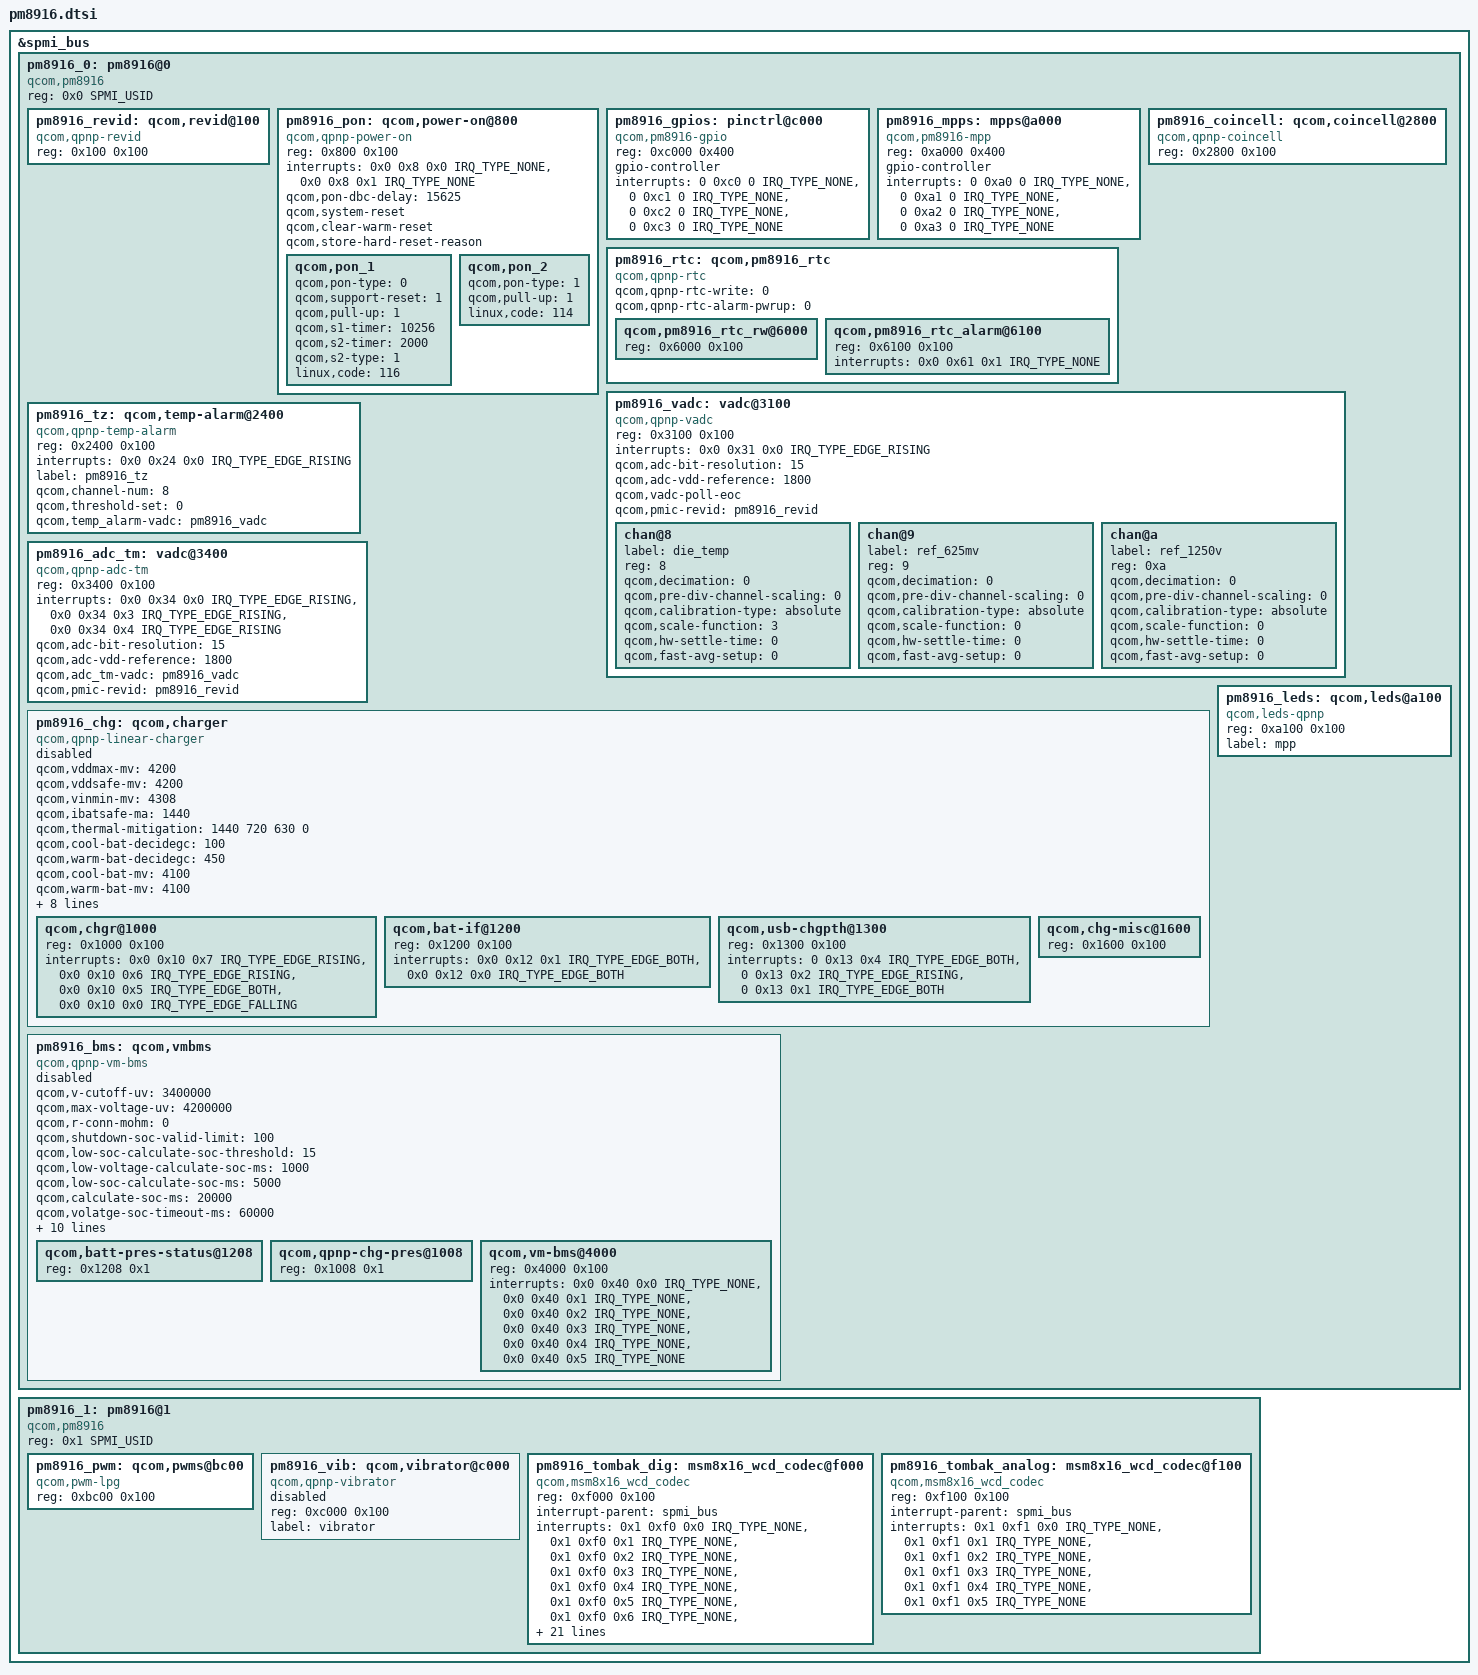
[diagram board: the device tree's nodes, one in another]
/* Copyright (c) 2013-2014, 2016-2018, The Linux Foundation. All rights reserved.
 *
 * This program is free software; you can redistribute it and/or modify
 * it under the terms of the GNU General Public License version 2 and
 * only version 2 as published by the Free Software Foundation.
 *
 * This program is distributed in the hope that it will be useful,
 * but WITHOUT ANY WARRANTY; without even the implied warranty of
 * MERCHANTABILITY or FITNESS FOR A PARTICULAR PURPOSE.  See the
 * GNU General Public License for more details.
 */

#include <dt-bindings/interrupt-controller/irq.h>
#include <dt-bindings/spmi/spmi.h>

&spmi_bus {

	pm8916_0: pm8916@0 {
		compatible = "qcom,pm8916", "qcom,spmi-pmic";
		reg = <0x0 SPMI_USID>;
		#address-cells = <1>;
		#size-cells = <1>;

		pm8916_revid: qcom,revid@100 {
			compatible = "qcom,qpnp-revid";
			reg = <0x100 0x100>;
		};

		pm8916_pon: qcom,power-on@800 {
			compatible = "qcom,qpnp-power-on";
			reg = <0x800 0x100>;
			interrupts = <0x0 0x8 0x0 IRQ_TYPE_NONE>,
				     <0x0 0x8 0x1 IRQ_TYPE_NONE>;
			interrupt-names = "kpdpwr", "resin";
			qcom,pon-dbc-delay = <15625>;
			qcom,system-reset;
			qcom,clear-warm-reset;
			qcom,store-hard-reset-reason;

			qcom,pon_1 {
				qcom,pon-type = <0>;
				qcom,support-reset = <1>;
				qcom,pull-up = <1>;
				qcom,s1-timer = <10256>;
				qcom,s2-timer = <2000>;
				qcom,s2-type = <1>;
				linux,code = <116>;
			};

			qcom,pon_2 {
				qcom,pon-type = <1>;
				qcom,pull-up = <1>;
				linux,code = <114>;
			};
		};

		pm8916_gpios: pinctrl@c000 {
			compatible = "qcom,pm8916-gpio";
			reg = <0xc000 0x400>;
			gpio-controller;
			#gpio-cells = <2>;
			interrupts = <0 0xc0 0 IRQ_TYPE_NONE>,
				     <0 0xc1 0 IRQ_TYPE_NONE>,
				     <0 0xc2 0 IRQ_TYPE_NONE>,
				     <0 0xc3 0 IRQ_TYPE_NONE>;
			interrupt-names = "pm8916_gpio1", "pm8916_gpio2",
					  "pm8916_gpio3", "pm8916_gpio4";
		};

		pm8916_mpps: mpps@a000 {
			compatible = "qcom,pm8916-mpp";
			reg = <0xa000 0x400>;
			gpio-controller;
			#gpio-cells = <2>;
			interrupts = <0 0xa0 0 IRQ_TYPE_NONE>,
				     <0 0xa1 0 IRQ_TYPE_NONE>,
				     <0 0xa2 0 IRQ_TYPE_NONE>,
				     <0 0xa3 0 IRQ_TYPE_NONE>;
			interrupt-names = "pm8916_mpp1", "pm8916_mpp2",
					  "pm8916_mpp3", "pm8916_mpp4";
		};

		pm8916_coincell: qcom,coincell@2800 {
			compatible = "qcom,qpnp-coincell";
			reg = <0x2800 0x100>;
		};

		pm8916_rtc: qcom,pm8916_rtc {
			compatible = "qcom,qpnp-rtc";
			#address-cells = <1>;
			#size-cells = <1>;
			qcom,qpnp-rtc-write = <0>;
			qcom,qpnp-rtc-alarm-pwrup = <0>;

			qcom,pm8916_rtc_rw@6000 {
				reg = <0x6000 0x100>;
			};
			qcom,pm8916_rtc_alarm@6100 {
				reg = <0x6100 0x100>;
				interrupts = <0x0 0x61 0x1 IRQ_TYPE_NONE>;
			};
		};

		pm8916_vadc: vadc@3100 {
			compatible = "qcom,qpnp-vadc";
			reg = <0x3100 0x100>;
			#address-cells = <1>;
			#size-cells = <0>;
			interrupts = <0x0 0x31 0x0 IRQ_TYPE_EDGE_RISING>;
			interrupt-names = "eoc-int-en-set";
			qcom,adc-bit-resolution = <15>;
			qcom,adc-vdd-reference = <1800>;
			qcom,vadc-poll-eoc;
			qcom,pmic-revid = <&pm8916_revid>;
			#thermal-sensor-cells = <1>;

			chan@8 {
				label = "die_temp";
				reg = <8>;
				qcom,decimation = <0>;
				qcom,pre-div-channel-scaling = <0>;
				qcom,calibration-type = "absolute";
				qcom,scale-function = <3>;
				qcom,hw-settle-time = <0>;
				qcom,fast-avg-setup = <0>;
			};

			chan@9 {
				label = "ref_625mv";
				reg = <9>;
				qcom,decimation = <0>;
				qcom,pre-div-channel-scaling = <0>;
				qcom,calibration-type = "absolute";
				qcom,scale-function = <0>;
				qcom,hw-settle-time = <0>;
				qcom,fast-avg-setup = <0>;
			};

			chan@a {
				label = "ref_1250v";
				reg = <0xa>;
				qcom,decimation = <0>;
				qcom,pre-div-channel-scaling = <0>;
				qcom,calibration-type = "absolute";
				qcom,scale-function = <0>;
				qcom,hw-settle-time = <0>;
				qcom,fast-avg-setup = <0>;
			};
		};

		pm8916_tz: qcom,temp-alarm@2400 {
			compatible = "qcom,qpnp-temp-alarm";
			reg = <0x2400 0x100>;
			interrupts = <0x0 0x24 0x0 IRQ_TYPE_EDGE_RISING>;
			label = "pm8916_tz";
			qcom,channel-num = <8>;
			qcom,threshold-set = <0>;
			qcom,temp_alarm-vadc = <&pm8916_vadc>;
			#thermal-sensor-cells = <0>;
		};

		pm8916_adc_tm: vadc@3400 {
			compatible = "qcom,qpnp-adc-tm";
			reg = <0x3400 0x100>;
			#address-cells = <1>;
			#size-cells = <0>;
			interrupts = <0x0 0x34 0x0 IRQ_TYPE_EDGE_RISING>,
				     <0x0 0x34 0x3 IRQ_TYPE_EDGE_RISING>,
				     <0x0 0x34 0x4 IRQ_TYPE_EDGE_RISING>;
			interrupt-names = "eoc-int-en-set",
					  "high-thr-en-set",
					  "low-thr-en-set";
			qcom,adc-bit-resolution = <15>;
			qcom,adc-vdd-reference = <1800>;
			qcom,adc_tm-vadc = <&pm8916_vadc>;
			qcom,pmic-revid = <&pm8916_revid>;
		};

		pm8916_chg: qcom,charger {
			compatible = "qcom,qpnp-linear-charger";
			#address-cells = <1>;
			#size-cells = <1>;

			qcom,vddmax-mv = <4200>;
			qcom,vddsafe-mv = <4200>;
			qcom,vinmin-mv = <4308>;
			qcom,ibatsafe-ma = <1440>;
			qcom,thermal-mitigation = <1440 720 630 0>;
			qcom,cool-bat-decidegc = <100>;
			qcom,warm-bat-decidegc = <450>;
			qcom,cool-bat-mv = <4100>;
			qcom,warm-bat-mv = <4100>;
			qcom,ibatmax-warm-ma = <360>;
			qcom,ibatmax-cool-ma = <360>;
			qcom,batt-hot-percentage = <25>;
			qcom,batt-cold-percentage = <80>;
			qcom,tchg-mins = <232>;
			qcom,resume-soc = <99>;
			qcom,chg-vadc = <&pm8916_vadc>;
			qcom,chg-adc_tm = <&pm8916_adc_tm>;

			status = "disabled";

			qcom,chgr@1000 {
				reg = <0x1000 0x100>;
				interrupts =
					<0x0 0x10 0x7 IRQ_TYPE_EDGE_RISING>,
					<0x0 0x10 0x6 IRQ_TYPE_EDGE_RISING>,
					<0x0 0x10 0x5 IRQ_TYPE_EDGE_BOTH>,
					<0x0 0x10 0x0 IRQ_TYPE_EDGE_FALLING>;
				interrupt-names = "chg-done",
						  "chg-failed",
						  "fast-chg-on",
						  "vbat-det-lo";
			};

			qcom,bat-if@1200 {
				reg = <0x1200 0x100>;
				interrupts = <0x0 0x12 0x1 IRQ_TYPE_EDGE_BOTH>,
					     <0x0 0x12 0x0 IRQ_TYPE_EDGE_BOTH>;
				interrupt-names = "bat-temp-ok",
						  "batt-pres";
			};

			qcom,usb-chgpth@1300 {
				reg = <0x1300 0x100>;
				interrupts =
					<0 0x13 0x4 IRQ_TYPE_EDGE_BOTH>,
					<0 0x13 0x2 IRQ_TYPE_EDGE_RISING>,
					<0 0x13 0x1 IRQ_TYPE_EDGE_BOTH>;
				interrupt-names = "usb-over-temp",
						  "chg-gone",
						  "usbin-valid";
			};

			qcom,chg-misc@1600 {
				reg = <0x1600 0x100>;
			};
		};

		pm8916_bms: qcom,vmbms {
			compatible = "qcom,qpnp-vm-bms";
			#address-cells = <1>;
			#size-cells = <1>;
			status = "disabled";

			qcom,v-cutoff-uv = <3400000>;
			qcom,max-voltage-uv = <4200000>;
			qcom,r-conn-mohm = <0>;
			qcom,shutdown-soc-valid-limit = <100>;
			qcom,low-soc-calculate-soc-threshold = <15>;
			qcom,low-voltage-calculate-soc-ms = <1000>;
			qcom,low-soc-calculate-soc-ms = <5000>;
			qcom,calculate-soc-ms = <20000>;
			qcom,volatge-soc-timeout-ms = <60000>;
			qcom,low-voltage-threshold = <3450000>;
			qcom,s3-ocv-tolerence-uv = <1200>;
			qcom,s2-fifo-length = <5>;
			qcom,low-soc-fifo-length = <2>;
			qcom,bms-vadc = <&pm8916_vadc>;
			qcom,bms-adc_tm = <&pm8916_adc_tm>;
			qcom,pmic-revid = <&pm8916_revid>;

			qcom,force-s3-on-suspend;
			qcom,force-s2-in-charging;
			qcom,report-charger-eoc;

			qcom,batt-pres-status@1208 {
				reg = <0x1208 0x1>;
			};

			qcom,qpnp-chg-pres@1008 {
				reg = <0x1008 0x1>;
			};

			qcom,vm-bms@4000 {
				reg = <0x4000 0x100>;
				interrupts = <0x0 0x40 0x0 IRQ_TYPE_NONE>,
					     <0x0 0x40 0x1 IRQ_TYPE_NONE>,
					     <0x0 0x40 0x2 IRQ_TYPE_NONE>,
					     <0x0 0x40 0x3 IRQ_TYPE_NONE>,
					     <0x0 0x40 0x4 IRQ_TYPE_NONE>,
					     <0x0 0x40 0x5 IRQ_TYPE_NONE>;

				interrupt-names = "leave_cv",
						  "enter_cv",
						  "good_ocv",
						  "ocv_thr",
						  "fifo_update_done",
						  "fsm_state_change";
			};
		};

		pm8916_leds: qcom,leds@a100 {
			compatible = "qcom,leds-qpnp";
			reg = <0xa100 0x100>;
			label = "mpp";
		};
	};

	pm8916_1: pm8916@1 {
		compatible = "qcom,pm8916", "qcom,spmi-pmic";
		reg = <0x1 SPMI_USID>;
		#address-cells = <1>;
		#size-cells = <1>;

		pm8916_pwm: qcom,pwms@bc00 {
			compatible = "qcom,pwm-lpg";
			reg = <0xbc00 0x100>;
			reg-names = "lpg-base";
			#pwm-cells = <2>;
		};

		pm8916_vib: qcom,vibrator@c000 {
			compatible = "qcom,qpnp-vibrator";
			reg = <0xc000 0x100>;
			label = "vibrator";
			status = "disabled";
		};

		pm8916_tombak_dig: msm8x16_wcd_codec@f000{
			compatible = "qcom,msm8x16_wcd_codec";
			reg = <0xf000 0x100>;
			interrupt-parent = <&spmi_bus>;
			interrupts = <0x1 0xf0 0x0 IRQ_TYPE_NONE>,
				     <0x1 0xf0 0x1 IRQ_TYPE_NONE>,
				     <0x1 0xf0 0x2 IRQ_TYPE_NONE>,
				     <0x1 0xf0 0x3 IRQ_TYPE_NONE>,
				     <0x1 0xf0 0x4 IRQ_TYPE_NONE>,
				     <0x1 0xf0 0x5 IRQ_TYPE_NONE>,
				     <0x1 0xf0 0x6 IRQ_TYPE_NONE>,
				     <0x1 0xf0 0x7 IRQ_TYPE_NONE>;
			interrupt-names = "spk_cnp_int",
					  "spk_clip_int",
					  "spk_ocp_int",
					  "ins_rem_det1",
					  "but_rel_det",
					  "but_press_det",
					  "ins_rem_det",
					  "mbhc_int";

			cdc-vdda-cp-supply = <&pm8916_s4>;
			qcom,cdc-vdda-cp-voltage = <1800000 2200000>;
			qcom,cdc-vdda-cp-current = <770000>;

			cdc-vdda-h-supply = <&pm8916_l5>;
			qcom,cdc-vdda-h-voltage = <1800000 1800000>;
			qcom,cdc-vdda-h-current = <20000>;

			cdc-vdd-px-supply = <&pm8916_s4>;
			qcom,cdc-vdd-px-voltage = <1800000 2200000>;
			qcom,cdc-vdd-px-current = <770000>;

			cdc-vdd-pa-supply = <&pm8916_l5>;
			qcom,cdc-vdd-pa-voltage = <1800000 1800000>;
			qcom,cdc-vdd-pa-current = <5000>;

			cdc-vdd-mic-bias-supply = <&pm8916_l13>;
			qcom,cdc-vdd-mic-bias-voltage = <3075000 3075000>;
			qcom,cdc-vdd-mic-bias-current = <25000>;

			qcom,cdc-mclk-clk-rate = <9600000>;

			qcom,cdc-static-supplies = "cdc-vdda-h",
						   "cdc-vdd-px",
						   "cdc-vdd-pa",
						   "cdc-vdda-cp";

			qcom,cdc-on-demand-supplies = "cdc-vdd-mic-bias";
			qcom,subsys-name = "modem";
		};

		pm8916_tombak_analog: msm8x16_wcd_codec@f100{
			compatible = "qcom,msm8x16_wcd_codec";
			reg = <0xf100 0x100>;
			interrupt-parent = <&spmi_bus>;
			interrupts = <0x1 0xf1 0x0 IRQ_TYPE_NONE>,
				     <0x1 0xf1 0x1 IRQ_TYPE_NONE>,
				     <0x1 0xf1 0x2 IRQ_TYPE_NONE>,
				     <0x1 0xf1 0x3 IRQ_TYPE_NONE>,
				     <0x1 0xf1 0x4 IRQ_TYPE_NONE>,
				     <0x1 0xf1 0x5 IRQ_TYPE_NONE>;
			interrupt-names = "ear_ocp_int",
					  "hphr_ocp_int",
					  "hphl_ocp_det",
					  "ear_cnp_int",
					  "hphr_cnp_int",
					  "hphl_cnp_int";
		};
	};
};
